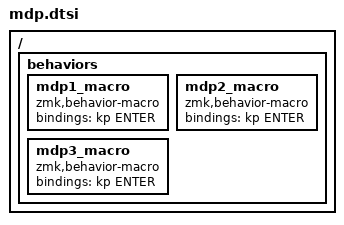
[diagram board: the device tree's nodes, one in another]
/* Public placeholders. Never commit personal key sequences or firmware. */
/ {
    behaviors {
        mdp1_macro: mdp1_macro {
            compatible = "zmk,behavior-macro";
            #binding-cells = <0>;
            bindings = <&kp ENTER>;
        };
        mdp2_macro: mdp2_macro {
            compatible = "zmk,behavior-macro";
            #binding-cells = <0>;
            bindings = <&kp ENTER>;
        };
        mdp3_macro: mdp3_macro {
            compatible = "zmk,behavior-macro";
            #binding-cells = <0>;
            bindings = <&kp ENTER>;
        };
    };
};
